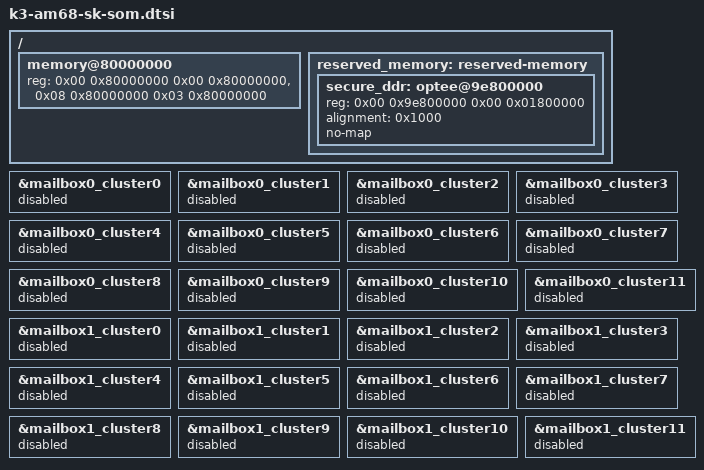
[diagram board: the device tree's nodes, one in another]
// SPDX-License-Identifier: GPL-2.0
/*
 * Copyright (C) 2022 Texas Instruments Incorporated - https://www.ti.com/
 */

/dts-v1/;

#include "k3-j721s2.dtsi"
#include <dt-bindings/gpio/gpio.h>

/ {
	memory@80000000 {
		device_type = "memory";
		/* 16 GB RAM */
		reg = <0x00 0x80000000 0x00 0x80000000>,
		      <0x08 0x80000000 0x03 0x80000000>;
	};

	/* Reserving memory regions still pending */
	reserved_memory: reserved-memory {
		#address-cells = <2>;
		#size-cells = <2>;
		ranges;

		secure_ddr: optee@9e800000 {
			reg = <0x00 0x9e800000 0x00 0x01800000>;
			alignment = <0x1000>;
			no-map;
		};
	};
};

&mailbox0_cluster0 {
	status = "disabled";
};

&mailbox0_cluster1 {
	status = "disabled";
};

&mailbox0_cluster2 {
	status = "disabled";
};

&mailbox0_cluster3 {
	status = "disabled";
};

&mailbox0_cluster4 {
	status = "disabled";
};

&mailbox0_cluster5 {
	status = "disabled";
};

&mailbox0_cluster6 {
	status = "disabled";
};

&mailbox0_cluster7 {
	status = "disabled";
};

&mailbox0_cluster8 {
	status = "disabled";
};

&mailbox0_cluster9 {
	status = "disabled";
};

&mailbox0_cluster10 {
	status = "disabled";
};

&mailbox0_cluster11 {
	status = "disabled";
};

&mailbox1_cluster0 {
	status = "disabled";
};

&mailbox1_cluster1 {
	status = "disabled";
};

&mailbox1_cluster2 {
	status = "disabled";
};

&mailbox1_cluster3 {
	status = "disabled";
};

&mailbox1_cluster4 {
	status = "disabled";
};

&mailbox1_cluster5 {
	status = "disabled";
};

&mailbox1_cluster6 {
	status = "disabled";
};

&mailbox1_cluster7 {
	status = "disabled";
};

&mailbox1_cluster8 {
	status = "disabled";
};

&mailbox1_cluster9 {
	status = "disabled";
};

&mailbox1_cluster10 {
	status = "disabled";
};

&mailbox1_cluster11 {
	status = "disabled";
};
